# GD32H77x_78x register map
File version: 1.0
CPU: CM7 r1p2, little endian, MPU, FPU, 4 interrupt priority bits
Registers are 32-bit, read-write, reset 0x0 unless marked. A register's access mark holds for its fields unless they carry their own. Offsets are from the block's base; [hi:lo] are bit positions; {n}, {i} and the like mark numbered series.

## ENET0_PTP — Ethernet: Precision time protocol
Base 0x40028700
Same registers: ENET1_PTP 0x4002A700
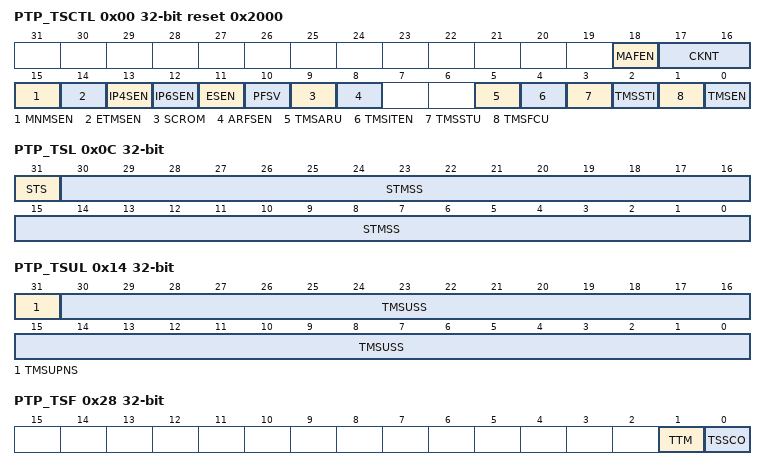
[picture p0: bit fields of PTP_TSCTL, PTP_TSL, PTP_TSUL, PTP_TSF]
0x00 PTP_TSCTL reset 0x2000 — Ethernet PTP time stamp control register (PTP_TSCTL)
  [18] MAFEN — MAC address filter enable for PTP frame
  [17:16] CKNT — Clock node type for time stamp
  [15] MNMSEN — Received master node message snapshot enable
  [14] ETMSEN — Received event type message snapshot enable
  [13] IP4SEN — Received IPv4 snapshot enable
  [12] IP6SEN — Received IPv6 snapshot enable
  [11] ESEN — Received Ethernet snapshot enable
  [10] PFSV — PTP frame snooping version
  [9] SCROM — Subsecond counter rollover mode
  [8] ARFSEN — All received frames snapshot enable
  [5] TMSARU — Time stamp addend register update
  [4] TMSITEN — Time stamp interrupt trigger enable
  [3] TMSSTU — Time stamp system time update
  [2] TMSSTI — Time stamp system time initialize
  [1] TMSFCU — Time stamp fine or coarse update
  [0] TMSEN — Time stamp enable
0x04 PTP_SSINC — Ethernet PTP subsecond increment register
  [7:0] STMSSI — System time subsecond increment
0x08 PTP_TSH ro — Ethernet PTP time stamp high register
  [31:0] STMS — System time second
0x0C PTP_TSL ro — Ethernet PTP time stamp low register (PTP_TSL)
  [31] STS — System time sign
  [30:0] STMSS — System time subseconds
0x10 PTP_TSUH — Ethernet PTP time stamp high update register
  [31:0] TMSUS — Time stamp update second
0x14 PTP_TSUL — Ethernet PTP time stamp low update register (PTP_TSUL)
  [31] TMSUPNS — Time stamp update positive or negative sign
  [30:0] TMSUSS — Time stamp update subseconds
0x18 PTP_TSADDEND — Ethernet PTP time stamp addend register
  [31:0] TMSA — Time stamp addend
0x1C PTP_ETH — Ethernet PTP expected time high register
  [31:0] ETSH — Expected time stamp high
0x20 PTP_ETL — Ethernet PTP expected time low register
  [31:0] ETSL — Expected time stamp low
0x28 PTP_TSF ro — Ethernet PTP time stamp flag register
  [1] TTM — Target time match
  [0] TSSCO — Timestamp second counter overflow
0x2C PTP_PPSCTL — Ethernet PTP PPS control register
  [3:0] PPSOFC — PPS output frequency configure

## EXTI — External interrupt/event controller
Base 0x58000000
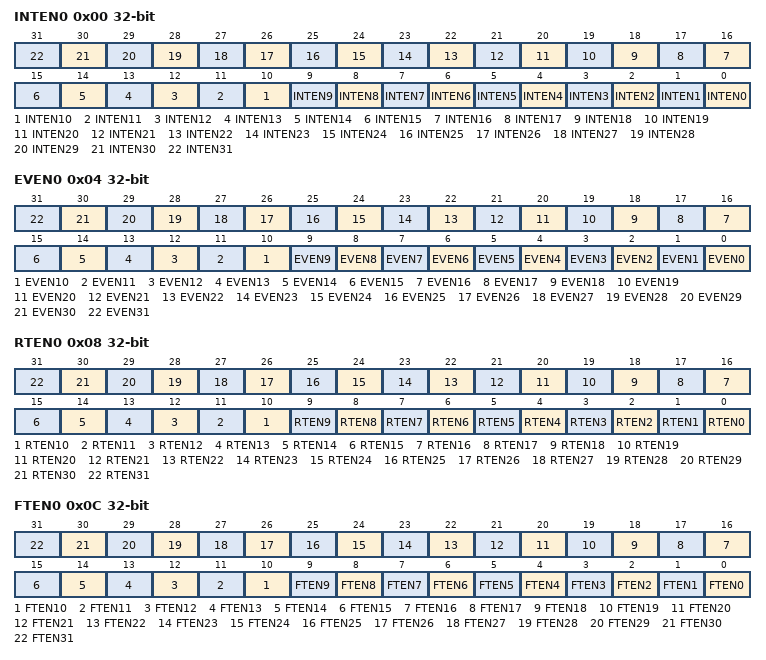
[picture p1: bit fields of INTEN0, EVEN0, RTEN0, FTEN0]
0x00 INTEN0 — Interrupt enable register 0 (EXTI_INTEN0)
  [n] INTEN{n} (n=0..31) — Enable Interrupt on line {n}
0x04 EVEN0 — Event enable register 0 (EXTI_EVEN0)
  [n] EVEN{n} (n=0..31) — Enable Event on line {n}
0x08 RTEN0 — Rising Edge Trigger Enable register 0 (EXTI_RTEN0)
  [n] RTEN{n} (n=0..31) — Rising edge trigger enable of line {n}
0x0C FTEN0 — Falling Egde Trigger Enable register 0 (EXTI_FTEN0)
  [n] FTEN{n} (n=0..31) — Falling edge trigger enable of line {n}
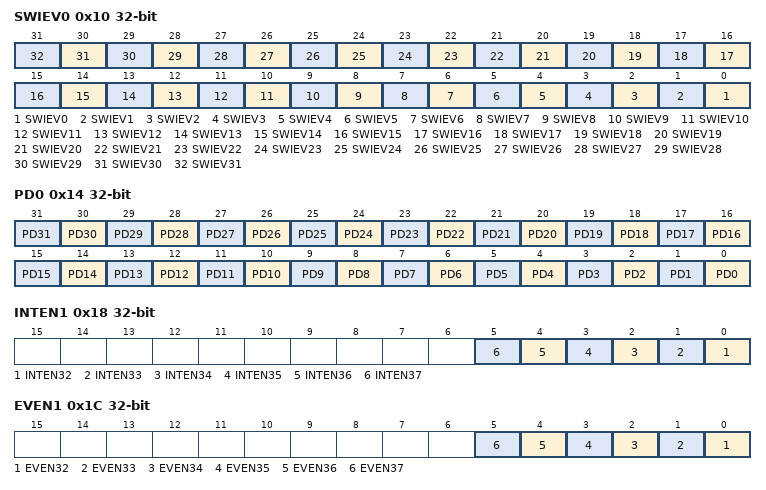
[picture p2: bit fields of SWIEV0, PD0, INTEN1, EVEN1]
0x10 SWIEV0 — Software interrupt event register (EXTI_SWIEV0)
  [n] SWIEV{n} (n=0..31) — Interrupt/Event software trigger on line {n}
0x14 PD0 — Pending register (EXTI_PD0)
  [n] PD{n} (n=0..31) — Interrupt pending status of line {n}
0x18 INTEN1 — Interrupt enable register 0 (EXTI_INTEN1)
  [n-32] INTEN{n} (n=32..37) — Enable Interrupt on line {n}
0x1C EVEN1 — Event enable register 1 (EXTI_EVEN1)
  [n-32] EVEN{n} (n=32..37) — Enable Event on line {n}
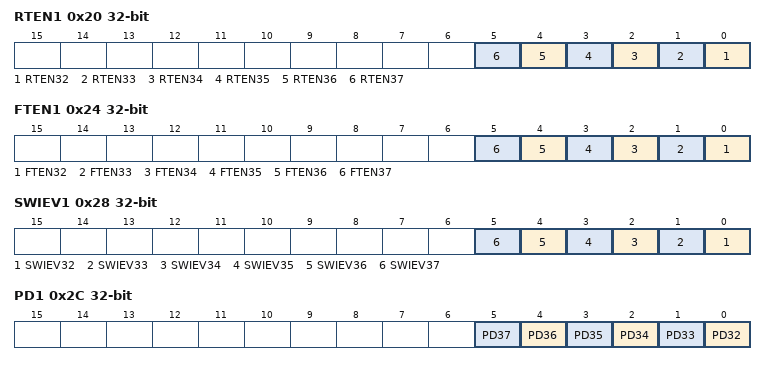
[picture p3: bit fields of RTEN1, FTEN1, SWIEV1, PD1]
0x20 RTEN1 — Rising Edge Trigger Enable register 1 (EXTI_RTEN1)
  [n-32] RTEN{n} (n=32..37) — Rising edge trigger enable of line {n}
0x24 FTEN1 — Falling Egde Trigger Enable register 1 (EXTI_FTEN1)
  [n-32] FTEN{n} (n=32..37) — Falling edge trigger enable of line {n}
0x28 SWIEV1 — Software interrupt event register (EXTI_SWIEV1)
  [n-32] SWIEV{n} (n=32..37) — Interrupt/Event software trigger on line {n}
0x2C PD1 — Pending register (EXTI_PD1)
  [n-32] PD{n} (n=32..37) — Interrupt pending status of line {n}

## FAC — Filter arithmetic accelerator
Base 0x48024800
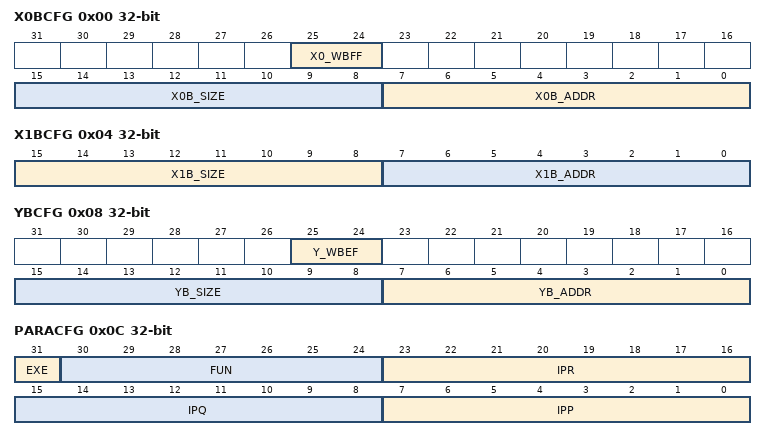
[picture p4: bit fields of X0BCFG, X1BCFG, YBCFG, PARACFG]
0x00 X0BCFG — FAC X0 buffer configure register
  [25:24] X0_WBFF — Buffer full flag of watermark
  [15:8] X0B_SIZE — X0 buffer size, the number of feed-forward taps
  [7:0] X0B_ADDR — X0 buffer base address
0x04 X1BCFG — FAC X1 buffer configure register
  [15:8] X1B_SIZE — X1 buffer size
  [7:0] X1B_ADDR — X1 buffer base address
0x08 YBCFG — FAC Y buffer configure register
  [25:24] Y_WBEF — Buffer empty flag of watermark
  [15:8] YB_SIZE — Y buffer size
  [7:0] YB_ADDR — Y buffer base address
0x0C PARACFG — FAC Parameter configure register
  [31] EXE — Execution
  [30:24] FUN — Function
  [23:16] IPR — Input parameter IPR
  [15:8] IPQ — Input parameter IPQ
  [7:0] IPP — Input parameter IPP
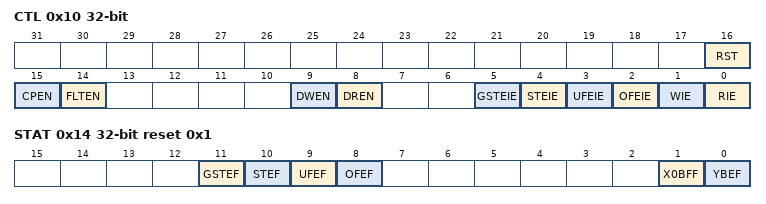
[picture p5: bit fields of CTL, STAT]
0x10 CTL — FAC Control register
  [16] RST — Reset FAC unit
  [15] CPEN — Clipping enable
  [14] FLTEN — Floating point format enable
  [9] DWEN — DMA write channel enable
  [8] DREN — DMA read channel enable
  [5] GSTEIE — Gain saturation error interrupt enable
  [4] STEIE — Saturation error interrupt enable
  [3] UFEIE — Underflow error interrupt enable
  [2] OFEIE — Overflow error interrupt enable
  [1] WIE — Write interrupt enable
  [0] RIE — Read interrupt enable
0x14 STAT ro reset 0x1 — FAC Status register
  [11] GSTEF — Gain saturation error flag, it is set when gain exceed range
  [10] STEF — Saturation error flag
  [9] UFEF — Underflow error flag
  [8] OFEF — Overflow error flag
  [1] X0BFF — X0 buffer full flag
  [0] YBEF — Y buffer empty flag
0x18 WDATA — FAC write data register
  [31:0] WDATA — Write data
0x1C RDATA — FAC read data register
  [31:0] RDATA — Read data
